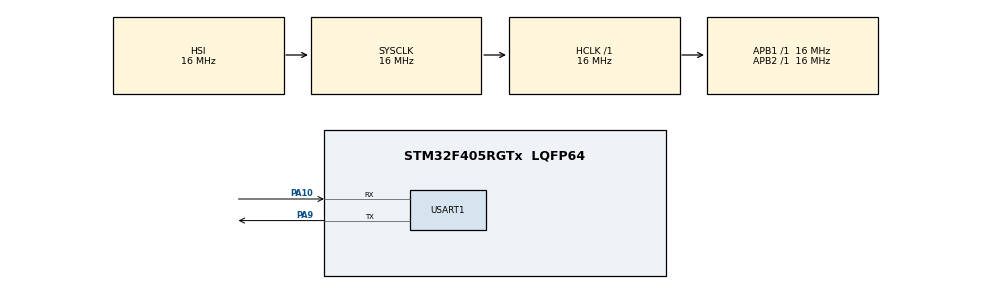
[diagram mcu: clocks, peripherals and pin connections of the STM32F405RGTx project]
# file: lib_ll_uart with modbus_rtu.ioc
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Dma.Request0=USART1_RX
Dma.Request1=USART1_TX
Dma.USART1_RX.0.Direction=DMA_PERIPH_TO_MEMORY
Dma.USART1_RX.0.FIFOMode=DMA_FIFOMODE_DISABLE
Dma.USART1_RX.0.Instance=DMA2_Stream2
Dma.USART1_RX.0.MemDataAlignment=DMA_MDATAALIGN_BYTE
Dma.USART1_RX.0.MemInc=DMA_MINC_ENABLE
Dma.USART1_RX.0.Mode=DMA_CIRCULAR
Dma.USART1_RX.0.PeriphDataAlignment=DMA_PDATAALIGN_BYTE
Dma.USART1_RX.0.PeriphInc=DMA_PINC_DISABLE
Dma.USART1_RX.0.Priority=DMA_PRIORITY_LOW
Dma.USART1_TX.1.Direction=DMA_MEMORY_TO_PERIPH
Dma.USART1_TX.1.FIFOMode=DMA_FIFOMODE_DISABLE
Dma.USART1_TX.1.Instance=DMA2_Stream7
Dma.USART1_TX.1.MemDataAlignment=DMA_MDATAALIGN_BYTE
Dma.USART1_TX.1.MemInc=DMA_MINC_ENABLE
Dma.USART1_TX.1.Mode=DMA_NORMAL
Dma.USART1_TX.1.PeriphDataAlignment=DMA_PDATAALIGN_BYTE
Dma.USART1_TX.1.PeriphInc=DMA_PINC_DISABLE
Dma.USART1_TX.1.Priority=DMA_PRIORITY_LOW
Mcu.Family=STM32F4
Mcu.Name=STM32F405RGTx
Mcu.Package=LQFP64
NVIC.DMA2_Stream2_IRQn=true\:1\:0\:true\:false\:true\:false\:true
NVIC.DMA2_Stream7_IRQn=true\:1\:0\:true\:false\:true\:false\:true
NVIC.PriorityGroup=NVIC_PRIORITYGROUP_4
NVIC.USART1_IRQn=true\:1\:0\:true\:false\:true\:true\:true
PA10.Mode=Asynchronous
PA10.Signal=USART1_RX
PA13.Mode=Trace_Asynchronous_SW
PA13.Signal=SYS_JTMS-SWDIO
PA14.Mode=Trace_Asynchronous_SW
PA14.Signal=SYS_JTCK-SWCLK
PA9.Mode=Asynchronous
PA9.Signal=USART1_TX
PB3.Mode=Trace_Asynchronous_SW
PB3.Signal=SYS_JTDO-SWO
ProjectManager.HeapSize=0x200
ProjectManager.StackSize=0x400
ProjectManager.TargetToolchain=STM32CubeIDE
RCC.AHBFreq_Value=16000000
RCC.APB1Freq_Value=16000000
RCC.APB2Freq_Value=16000000
RCC.CortexFreq_Value=16000000
RCC.HSE_VALUE=25000000
RCC.HSI_VALUE=16000000
RCC.LSE_VALUE=32768
RCC.SYSCLKFreq_VALUE=16000000
RCC.VCOOutputFreq_Value=192000000
USART1.VirtualMode=VM_ASYNC
board=custom

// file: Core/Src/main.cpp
/* USER CODE BEGIN Header */
/**
  ******************************************************************************
  * @file           : main.c
  * @brief          : Main program body
  ******************************************************************************
  * @attention
  *
  * <h2><center>&copy; Copyright (c) 2021 STMicroelectronics.
  * All rights reserved.</center></h2>
  *
  * This software component is licensed by ST under BSD 3-Clause license,
  * the "License"; You may not use this file except in compliance with the
  * License. You may obtain a copy of the License at:
  *                        opensource.org/licenses/BSD-3-Clause
  *
  ******************************************************************************
  */
/* USER CODE END Header */
#include "main.h"

/* USER CODE BEGIN Includes */

#include "lib.h"

/* USER CODE END Includes */

void SystemClock_Config(void);
static void MX_GPIO_Init(void);
static void MX_DMA_Init(void);
static void MX_USART1_UART_Init(void);

/* USER CODE BEGIN 0 */

#define FAKEHEAP_BUFSIZE 256 // 定义缓存长度
static uint8_t fakeheapbuf[FAKEHEAP_BUFSIZE] = { 0 }; // 声明一个数组作为缓存
Lib_FakeHeap fakeheap(fakeheapbuf, FAKEHEAP_BUFSIZE); // 将数组绑定到Lib_FakeHeap对象

////////////////////////////////////////

Lib_LL_UartTx uarttx(USART1, DMA2, LL_DMA_STREAM_7); // Lib_LL_UartTx对象声明

////////////////////////////////////////

static uint8_t uartrxbuf[LIB_LL_MODBUS_RTU_RXBUF_SIZE] = { 0 }; // 串口接收缓存
Lib_LL_ModbusRtu_Slave modbus(uartrxbuf); // 协议对象，本例程中作为从机使用
Lib_LL_UartRx uartrx(USART1, DMA2, LL_DMA_STREAM_2, uartrxbuf, LIB_LL_MODBUS_RTU_RXBUF_SIZE, [](uint16_t rxrear) {
	modbus.parse(rxrear);
}); // Lib_LL_UartRx对象声明

void command03(uint8_t addr, uint16_t msgsize) { // 指令回调函数
	if (addr == 0) {
		return; // 通常情况下从机收到广播消息只处理不响应
	}
	uint8_t *ptr = fakeheap.get(msgsize); // 从fakeheap中申请长度为msgsize的空间
	modbus.read(ptr, 0, msgsize); // 读取当前消息数据到ptr指向的区域
	uarttx.write(ptr, msgsize); // 通过串口发送ptr指向区域的消息
}

void command10(uint8_t addr, uint16_t msgsize) { // 指令回调函数
	if (addr == 0) {
		return; // 通常情况下从机收到广播消息只处理不响应
	}
	uint8_t *ptr = fakeheap.get(6); // 从fakeheap中申请长度为6的空间
	ptr[0] = 0xAA;
	ptr[1] = 0xBB;
	ptr[2] = 0xCC;
	ptr[3] = 0xDD;
	ptr[4] = 0xEE;
	ptr[5] = 0xFF;
	uarttx.write(ptr, 6); // 通过串口发送ptr指向区域的消息
}

/* USER CODE END 0 */

int main(void)
{

  /* MCU Configuration--------------------------------------------------------*/

  /* Reset of all peripherals, Initializes the Flash interface and the Systick. */
  HAL_Init();

  /* Configure the system clock */
  SystemClock_Config();

  /* Initialize all configured peripherals */
  MX_GPIO_Init();
  MX_DMA_Init();
  MX_USART1_UART_Init();
  /* USER CODE BEGIN 2 */

	modbus.setAddr(2); //将自身地址设置为2
	modbus.addCbFn03(command03); // 绑定指令，功能码为0x03的消息时触发
	modbus.addCbFn10(command10); // 绑定指令，功能码为0x10的消息时触发
	// 根据上面的设置，在收到地址为0或2，功能码为0x03的消息时将触发command03()函数
	// 例如收到 02 03 00 00 00 01 84 39 时将触发command03()函数
	// 在收到地址为0或2，功能码为0x10的消息时将触发command10()函数
	// 例如收到 02 10 00 00 00 01 02 AA BB 8C 73 将触发command10()函数
	// 收到 00 10 00 00 00 01 02 AA BB 95 13 也可触发command10()函数

	uartrx.listen(); // 启动串口接收监听

  /* USER CODE END 2 */

  /* Infinite loop */
  while (1)
  {

  }
}

void SystemClock_Config(void)
{
  RCC_OscInitTypeDef RCC_OscInitStruct = {0};
  RCC_ClkInitTypeDef RCC_ClkInitStruct = {0};

  /** Configure the main internal regulator output voltage
  */
  __HAL_RCC_PWR_CLK_ENABLE();
  __HAL_PWR_VOLTAGESCALING_CONFIG(PWR_REGULATOR_VOLTAGE_SCALE1);
  /** Initializes the RCC Oscillators according to the specified parameters
  * in the RCC_OscInitTypeDef structure.
  */
  RCC_OscInitStruct.OscillatorType = RCC_OSCILLATORTYPE_HSI;
  RCC_OscInitStruct.HSIState = RCC_HSI_ON;
  RCC_OscInitStruct.HSICalibrationValue = RCC_HSICALIBRATION_DEFAULT;
  RCC_OscInitStruct.PLL.PLLState = RCC_PLL_NONE;
  if (HAL_RCC_OscConfig(&RCC_OscInitStruct) != HAL_OK)
  {
    Error_Handler();
  }
  /** Initializes the CPU, AHB and APB buses clocks
  */
  RCC_ClkInitStruct.ClockType = RCC_CLOCKTYPE_HCLK|RCC_CLOCKTYPE_SYSCLK
                              |RCC_CLOCKTYPE_PCLK1|RCC_CLOCKTYPE_PCLK2;
  RCC_ClkInitStruct.SYSCLKSource = RCC_SYSCLKSOURCE_HSI;
  RCC_ClkInitStruct.AHBCLKDivider = RCC_SYSCLK_DIV1;
  RCC_ClkInitStruct.APB1CLKDivider = RCC_HCLK_DIV1;
  RCC_ClkInitStruct.APB2CLKDivider = RCC_HCLK_DIV1;

  if (HAL_RCC_ClockConfig(&RCC_ClkInitStruct, FLASH_LATENCY_0) != HAL_OK)
  {
    Error_Handler();
  }
}

static void MX_USART1_UART_Init(void)
{

  LL_USART_InitTypeDef USART_InitStruct = {0};

  LL_GPIO_InitTypeDef GPIO_InitStruct = {0};

  /* Peripheral clock enable */
  LL_APB2_GRP1_EnableClock(LL_APB2_GRP1_PERIPH_USART1);

  LL_AHB1_GRP1_EnableClock(LL_AHB1_GRP1_PERIPH_GPIOA);
  /**USART1 GPIO Configuration
  PA9   ------> USART1_TX
  PA10   ------> USART1_RX
  */
  GPIO_InitStruct.Pin = LL_GPIO_PIN_9|LL_GPIO_PIN_10;
  GPIO_InitStruct.Mode = LL_GPIO_MODE_ALTERNATE;
  GPIO_InitStruct.Speed = LL_GPIO_SPEED_FREQ_VERY_HIGH;
  GPIO_InitStruct.OutputType = LL_GPIO_OUTPUT_PUSHPULL;
  GPIO_InitStruct.Pull = LL_GPIO_PULL_NO;
  GPIO_InitStruct.Alternate = LL_GPIO_AF_7;
  LL_GPIO_Init(GPIOA, &GPIO_InitStruct);

  /* USART1 DMA Init */

  /* USART1_RX Init */
  LL_DMA_SetChannelSelection(DMA2, LL_DMA_STREAM_2, LL_DMA_CHANNEL_4);

  LL_DMA_SetDataTransferDirection(DMA2, LL_DMA_STREAM_2, LL_DMA_DIRECTION_PERIPH_TO_MEMORY);

  LL_DMA_SetStreamPriorityLevel(DMA2, LL_DMA_STREAM_2, LL_DMA_PRIORITY_LOW);

  LL_DMA_SetMode(DMA2, LL_DMA_STREAM_2, LL_DMA_MODE_CIRCULAR);

  LL_DMA_SetPeriphIncMode(DMA2, LL_DMA_STREAM_2, LL_DMA_PERIPH_NOINCREMENT);

  LL_DMA_SetMemoryIncMode(DMA2, LL_DMA_STREAM_2, LL_DMA_MEMORY_INCREMENT);

  LL_DMA_SetPeriphSize(DMA2, LL_DMA_STREAM_2, LL_DMA_PDATAALIGN_BYTE);

  LL_DMA_SetMemorySize(DMA2, LL_DMA_STREAM_2, LL_DMA_MDATAALIGN_BYTE);

  LL_DMA_DisableFifoMode(DMA2, LL_DMA_STREAM_2);

  /* USART1_TX Init */
  LL_DMA_SetChannelSelection(DMA2, LL_DMA_STREAM_7, LL_DMA_CHANNEL_4);

  LL_DMA_SetDataTransferDirection(DMA2, LL_DMA_STREAM_7, LL_DMA_DIRECTION_MEMORY_TO_PERIPH);

  LL_DMA_SetStreamPriorityLevel(DMA2, LL_DMA_STREAM_7, LL_DMA_PRIORITY_LOW);

  LL_DMA_SetMode(DMA2, LL_DMA_STREAM_7, LL_DMA_MODE_NORMAL);

  LL_DMA_SetPeriphIncMode(DMA2, LL_DMA_STREAM_7, LL_DMA_PERIPH_NOINCREMENT);

  LL_DMA_SetMemoryIncMode(DMA2, LL_DMA_STREAM_7, LL_DMA_MEMORY_INCREMENT);

  LL_DMA_SetPeriphSize(DMA2, LL_DMA_STREAM_7, LL_DMA_PDATAALIGN_BYTE);

  LL_DMA_SetMemorySize(DMA2, LL_DMA_STREAM_7, LL_DMA_MDATAALIGN_BYTE);

  LL_DMA_DisableFifoMode(DMA2, LL_DMA_STREAM_7);

  /* USART1 interrupt Init */
  NVIC_SetPriority(USART1_IRQn, NVIC_EncodePriority(NVIC_GetPriorityGrouping(),1, 0));
  NVIC_EnableIRQ(USART1_IRQn);

  USART_InitStruct.BaudRate = 115200;
  USART_InitStruct.DataWidth = LL_USART_DATAWIDTH_8B;
  USART_InitStruct.StopBits = LL_USART_STOPBITS_1;
  USART_InitStruct.Parity = LL_USART_PARITY_NONE;
  USART_InitStruct.TransferDirection = LL_USART_DIRECTION_TX_RX;
  USART_InitStruct.HardwareFlowControl = LL_USART_HWCONTROL_NONE;
  USART_InitStruct.OverSampling = LL_USART_OVERSAMPLING_16;
  LL_USART_Init(USART1, &USART_InitStruct);
  LL_USART_ConfigAsyncMode(USART1);
  LL_USART_Enable(USART1);

}

static void MX_DMA_Init(void)
{

  /* DMA controller clock enable */
  __HAL_RCC_DMA2_CLK_ENABLE();

  /* DMA interrupt init */
  /* DMA2_Stream2_IRQn interrupt configuration */
  NVIC_SetPriority(DMA2_Stream2_IRQn, NVIC_EncodePriority(NVIC_GetPriorityGrouping(),1, 0));
  NVIC_EnableIRQ(DMA2_Stream2_IRQn);
  /* DMA2_Stream7_IRQn interrupt configuration */
  NVIC_SetPriority(DMA2_Stream7_IRQn, NVIC_EncodePriority(NVIC_GetPriorityGrouping(),1, 0));
  NVIC_EnableIRQ(DMA2_Stream7_IRQn);

}

static void MX_GPIO_Init(void)
{

  /* GPIO Ports Clock Enable */
  __HAL_RCC_GPIOA_CLK_ENABLE();
  __HAL_RCC_GPIOB_CLK_ENABLE();

}

void Error_Handler(void)
{
  __disable_irq();
  while (1)
  {
  }
}

/************************ (C) COPYRIGHT STMicroelectronics *****END OF FILE****/
